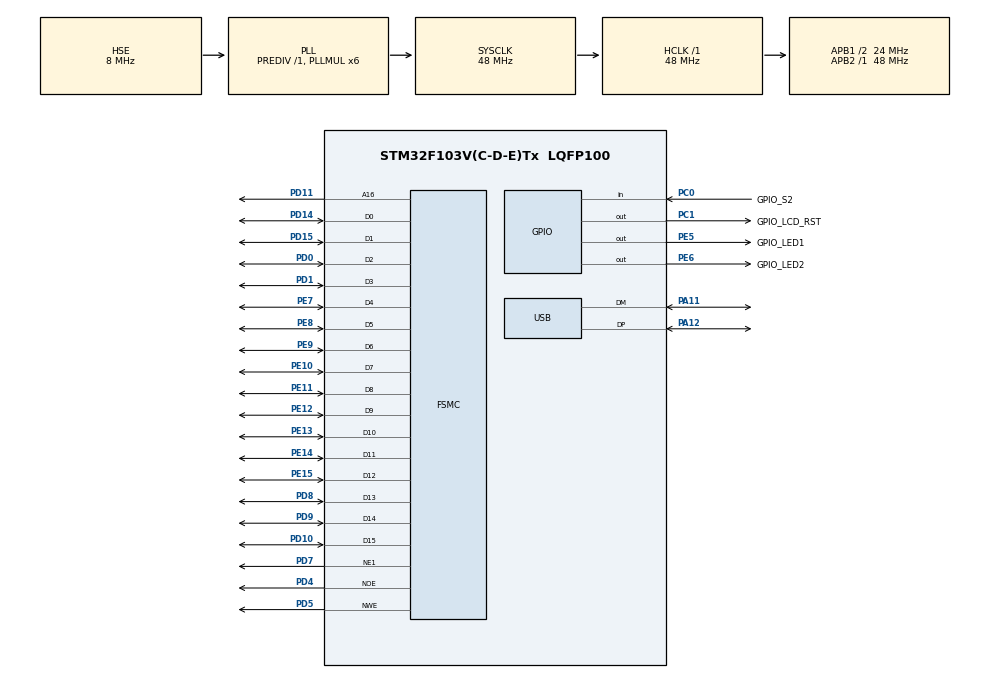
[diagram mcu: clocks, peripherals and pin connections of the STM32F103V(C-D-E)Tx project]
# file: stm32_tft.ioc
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Mcu.Family=STM32F1
Mcu.Name=STM32F103V(C-D-E)Tx
Mcu.Package=LQFP100
NVIC.PriorityGroup=NVIC_PRIORITYGROUP_4
NVIC.TIM6_IRQn=true\:0\:0\:false\:false\:true
NVIC.USB_LP_CAN1_RX0_IRQn=true\:0\:0\:false\:false\:true
OSC_IN.Mode=HSE-External-Oscillator
OSC_IN.Signal=RCC_OSC_IN
OSC_OUT.Mode=HSE-External-Oscillator
OSC_OUT.Signal=RCC_OSC_OUT
PA11.Mode=Device
PA11.Signal=USB_DM
PA12.Mode=Device
PA12.Signal=USB_DP
PA13.Mode=Serial_Wire
PA13.Signal=SYS_JTMS-SWDIO
PA14.Mode=Serial_Wire
PA14.Signal=SYS_JTCK-SWCLK
PC0.GPIO_Label=GPIO_S2
PC0.Signal=GPIO_Input
PC1.GPIO_Label=GPIO_LCD_RST
PC1.Signal=GPIO_Output
PC14-OSC32_IN.Mode=LSE-External-Oscillator
PC14-OSC32_IN.Signal=RCC_OSC32_IN
PC15-OSC32_OUT.Mode=LSE-External-Oscillator
PC15-OSC32_OUT.Signal=RCC_OSC32_OUT
PD0.Mode=16b-d1
PD0.Signal=FSMC_D2
PD1.Mode=16b-d1
PD1.Signal=FSMC_D3
PD10.Mode=16b-d1
PD10.Signal=FSMC_D15
PD11.Mode=A16_1
PD11.Signal=FSMC_A16
PD14.Mode=16b-d1
PD14.Signal=FSMC_D0
PD15.Mode=16b-d1
PD15.Signal=FSMC_D1
PD4.Mode=Lcd1
PD4.Signal=FSMC_NOE
PD5.Mode=Lcd1
PD5.Signal=FSMC_NWE
PD7.Mode=NorPsramChipSelect1_1
PD7.Signal=FSMC_NE1
PD8.Mode=16b-d1
PD8.Signal=FSMC_D13
PD9.Mode=16b-d1
PD9.Signal=FSMC_D14
PE10.Mode=16b-d1
PE10.Signal=FSMC_D7
PE11.Mode=16b-d1
PE11.Signal=FSMC_D8
PE12.Mode=16b-d1
PE12.Signal=FSMC_D9
PE13.Mode=16b-d1
PE13.Signal=FSMC_D10
PE14.Mode=16b-d1
PE14.Signal=FSMC_D11
PE15.Mode=16b-d1
PE15.Signal=FSMC_D12
PE5.GPIO_Label=GPIO_LED1
PE5.Signal=GPIO_Output
PE6.GPIO_Label=GPIO_LED2
PE6.Signal=GPIO_Output
PE7.Mode=16b-d1
PE7.Signal=FSMC_D4
PE8.Mode=16b-d1
PE8.Signal=FSMC_D5
PE9.Mode=16b-d1
PE9.Signal=FSMC_D6
ProjectManager.HeapSize=0x200
ProjectManager.StackSize=0x400
ProjectManager.TargetToolchain=SW4STM32
RCC.AHBFreq_Value=48000000
RCC.APB1CLKDivider=RCC_HCLK_DIV2
RCC.APB1Freq_Value=24000000
RCC.APB1TimFreq_Value=48000000
RCC.APB2Freq_Value=48000000
RCC.APB2TimFreq_Value=48000000
RCC.EnbaleCSS=true
RCC.HCLKFreq_Value=48000000
RCC.HSIState=RCC_HSI_ON
RCC.PLLMUL=RCC_PLL_MUL6
RCC.PLLSourceVirtual=RCC_PLLSOURCE_HSE
RCC.RTCClockSelection=RCC_RTCCLKSOURCE_LSE
RCC.SYSCLKFreq_VALUE=48000000
RCC.SYSCLKSource=RCC_SYSCLKSOURCE_PLLCLK
RCC.USBFreq_Value=48000000
TIM6.Period=48000
TIM6.Prescaler=0
TIM6.TIM_MasterOutputTrigger=TIM_TRGO_ENABLE
USB.ep0_mps=DEP0CTL_MPS_64
USB_DEVICE.CLASS_NAME_FS=CDC
USB_DEVICE.USBD_HandleTypeDef=hUsbDeviceFS
USB_DEVICE.VirtualMode=Cdc
USB_DEVICE.VirtualModeFS=Cdc_FS
VP_RTC_VS_RTC_Activate.Mode=RTC_Enabled
VP_TIM6_VS_ClockSourceINT.Mode=Enable_Timer
VP_USB_DEVICE_VS_USB_DEVICE_CDC_FS.Mode=CDC_FS
board=stm32_tft

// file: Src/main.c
/**
  ******************************************************************************
  * File Name          : main.c
  * Description        : Main program body
  ******************************************************************************
  *
  * Copyright (c) 2017 STMicroelectronics International N.V.
  * All rights reserved.
  *
  * Redistribution and use in source and binary forms, with or without
  * modification, are permitted, provided that the following conditions are met:
  *
  * 1. Redistribution of source code must retain the above copyright notice,
  *    this list of conditions and the following disclaimer.
  * 2. Redistributions in binary form must reproduce the above copyright notice,
  *    this list of conditions and the following disclaimer in the documentation
  *    and/or other materials provided with the distribution.
  * 3. Neither the name of STMicroelectronics nor the names of other
  *    contributors to this software may be used to endorse or promote products
  *    derived from this software without specific written permission.
  * 4. This software, including modifications and/or derivative works of this
  *    software, must execute solely and exclusively on microcontroller or
  *    microprocessor devices manufactured by or for STMicroelectronics.
  * 5. Redistribution and use of this software other than as permitted under
  *    this license is void and will automatically terminate your rights under
  *    this license.
  *
  * THIS SOFTWARE IS PROVIDED BY STMICROELECTRONICS AND CONTRIBUTORS "AS IS"
  * AND ANY EXPRESS, IMPLIED OR STATUTORY WARRANTIES, INCLUDING, BUT NOT
  * LIMITED TO, THE IMPLIED WARRANTIES OF MERCHANTABILITY, FITNESS FOR A
  * PARTICULAR PURPOSE AND NON-INFRINGEMENT OF THIRD PARTY INTELLECTUAL PROPERTY
  * RIGHTS ARE DISCLAIMED TO THE FULLEST EXTENT PERMITTED BY LAW. IN NO EVENT
  * SHALL STMICROELECTRONICS OR CONTRIBUTORS BE LIABLE FOR ANY DIRECT, INDIRECT,
  * INCIDENTAL, SPECIAL, EXEMPLARY, OR CONSEQUENTIAL DAMAGES (INCLUDING, BUT NOT
  * LIMITED TO, PROCUREMENT OF SUBSTITUTE GOODS OR SERVICES; LOSS OF USE, DATA,
  * OR PROFITS; OR BUSINESS INTERRUPTION) HOWEVER CAUSED AND ON ANY THEORY OF
  * LIABILITY, WHETHER IN CONTRACT, STRICT LIABILITY, OR TORT (INCLUDING
  * NEGLIGENCE OR OTHERWISE) ARISING IN ANY WAY OUT OF THE USE OF THIS SOFTWARE,
  * EVEN IF ADVISED OF THE POSSIBILITY OF SUCH DAMAGE.
  *
  ******************************************************************************
  */
#include "main.h"
#include "stm32f1xx_hal.h"
#include "usb_device.h"

/* USER CODE BEGIN Includes */
//#include "stm32_microrl_misc.h"
#include "event_queue.h"
#include "timer.h"
/* USER CODE END Includes */

RTC_HandleTypeDef hrtc;

TIM_HandleTypeDef htim6;

/* USER CODE BEGIN PV */
/* Private variables ---------------------------------------------------------*/

/* USER CODE END PV */

void SystemClock_Config(void);
void Error_Handler(void);
static void MX_GPIO_Init(void);
static void MX_RTC_Init(void);
static void MX_TIM6_Init(void);

/* USER CODE BEGIN PFP */
/* Private function prototypes -----------------------------------------------*/

/* USER CODE END PFP */

/* USER CODE BEGIN 0 */
//arm-none-eabi-objcopy -O binary "${BuildArtifactFileBaseName}.elf" "${BuildArtifactFileBaseName}.bin" && arm-none-eabi-size "${BuildArtifactFileName}"
//arm-none-eabi-objcopy -O ihex "${BuildArtifactFileBaseName}.elf" "${BuildArtifactFileBaseName}.hex"
/* USER CODE END 0 */

int main(void)
{

  /* USER CODE BEGIN 1 */
	eq_queue_element_s ev;
  /* USER CODE END 1 */

  /* MCU Configuration----------------------------------------------------------*/

  /* Reset of all peripherals, Initializes the Flash interface and the Systick. */
  HAL_Init();

  /* Configure the system clock */
  SystemClock_Config();

  /* Initialize all configured peripherals */
  MX_GPIO_Init();
  MX_RTC_Init();
  MX_TIM6_Init();
  MX_USB_DEVICE_Init();

  /* USER CODE BEGIN 2 */
//  init();
  HAL_TIM_Base_Start_IT(&htim6);
  HAL_GPIO_WritePin(GPIO_LED1_GPIO_Port, GPIO_LED1_Pin, GPIO_PIN_SET);
  HAL_GPIO_WritePin(GPIO_LED2_GPIO_Port, GPIO_LED2_Pin, GPIO_PIN_RESET);
  TIMER_StartAuto(1, 50);
  /* USER CODE END 2 */

  /* Infinite loop */
  /* USER CODE BEGIN WHILE */
  while (1)
  {
//	  TERM_Task();
	  TIMER_Task();
	  do {
		  EQ_GetEvent(&ev);
		  switch(ev.event){
		  case NO_EVENT:
			  break;
		  case CMD_WIDTH:
		  	  TIMER_StartAuto(1, ev.param.uiParam);
		  	  break;
		  case CMD_HV_ON:
			  HAL_GPIO_WritePin(GPIO_LED2_GPIO_Port, GPIO_LED2_Pin, GPIO_PIN_RESET);
			  break;
		  case CMD_HV_OFF:
			  HAL_GPIO_WritePin(GPIO_LED2_GPIO_Port, GPIO_LED2_Pin, GPIO_PIN_SET);
			  break;
		  case TIMER1_EXPIRED:
			  //HAL_GPIO_TogglePin(GPIO_LED1_GPIO_Port, GPIO_LED1_Pin);
			  //HAL_GPIO_TogglePin(GPIO_LED2_GPIO_Port, GPIO_LED2_Pin);
			  break;
		  default:
			  break;
		  }
	  } while (ev.event != NO_EVENT);
  }
  /* USER CODE END WHILE */

  /* USER CODE BEGIN 3 */
//	  uint8_t Buf[100] = "";
//	  sprintf(Buf,"cnt 0x%08d    ", int_counter);
//
//	  CDC_Transmit_FS(Buf, 15);
//	  HAL_Delay(1000);
//	  if (1 == blink)
//	  {
//		  HAL_GPIO_WritePin(GPIO_LED1_GPIO_Port, GPIO_LED1_Pin, GPIO_PIN_SET);
//		  blink = 0;
//	  } else {
//		  HAL_GPIO_WritePin(GPIO_LED1_GPIO_Port, GPIO_LED1_Pin, GPIO_PIN_RESET);
//		  blink = 1;
//	  }

  /* USER CODE END 3 */

}

/** System Clock Configuration
*/
void SystemClock_Config(void)
{

  RCC_OscInitTypeDef RCC_OscInitStruct;
  RCC_ClkInitTypeDef RCC_ClkInitStruct;
  RCC_PeriphCLKInitTypeDef PeriphClkInit;

    /**Initializes the CPU, AHB and APB busses clocks
    */
  RCC_OscInitStruct.OscillatorType = RCC_OSCILLATORTYPE_HSE|RCC_OSCILLATORTYPE_LSE;
  RCC_OscInitStruct.HSEState = RCC_HSE_ON;
  RCC_OscInitStruct.HSEPredivValue = RCC_HSE_PREDIV_DIV1;
  RCC_OscInitStruct.LSEState = RCC_LSE_ON;
  RCC_OscInitStruct.HSIState = RCC_HSI_ON;
  RCC_OscInitStruct.PLL.PLLState = RCC_PLL_ON;
  RCC_OscInitStruct.PLL.PLLSource = RCC_PLLSOURCE_HSE;
  RCC_OscInitStruct.PLL.PLLMUL = RCC_PLL_MUL6;
  if (HAL_RCC_OscConfig(&RCC_OscInitStruct) != HAL_OK)
  {
    Error_Handler();
  }

    /**Initializes the CPU, AHB and APB busses clocks
    */
  RCC_ClkInitStruct.ClockType = RCC_CLOCKTYPE_HCLK|RCC_CLOCKTYPE_SYSCLK
                              |RCC_CLOCKTYPE_PCLK1|RCC_CLOCKTYPE_PCLK2;
  RCC_ClkInitStruct.SYSCLKSource = RCC_SYSCLKSOURCE_PLLCLK;
  RCC_ClkInitStruct.AHBCLKDivider = RCC_SYSCLK_DIV1;
  RCC_ClkInitStruct.APB1CLKDivider = RCC_HCLK_DIV2;
  RCC_ClkInitStruct.APB2CLKDivider = RCC_HCLK_DIV1;

  if (HAL_RCC_ClockConfig(&RCC_ClkInitStruct, FLASH_LATENCY_1) != HAL_OK)
  {
    Error_Handler();
  }

  PeriphClkInit.PeriphClockSelection = RCC_PERIPHCLK_RTC|RCC_PERIPHCLK_USB;
  PeriphClkInit.RTCClockSelection = RCC_RTCCLKSOURCE_LSE;
  PeriphClkInit.UsbClockSelection = RCC_USBCLKSOURCE_PLL;
  if (HAL_RCCEx_PeriphCLKConfig(&PeriphClkInit) != HAL_OK)
  {
    Error_Handler();
  }

    /**Enables the Clock Security System
    */
  HAL_RCC_EnableCSS();

    /**Configure the Systick interrupt time
    */
  HAL_SYSTICK_Config(HAL_RCC_GetHCLKFreq()/1000);

    /**Configure the Systick
    */
  HAL_SYSTICK_CLKSourceConfig(SYSTICK_CLKSOURCE_HCLK);

  /* SysTick_IRQn interrupt configuration */
  HAL_NVIC_SetPriority(SysTick_IRQn, 0, 0);
}

/* RTC init function */
static void MX_RTC_Init(void)
{

    /**Initialize RTC Only
    */
  hrtc.Instance = RTC;
  hrtc.Init.AsynchPrediv = RTC_AUTO_1_SECOND;
  hrtc.Init.OutPut = RTC_OUTPUTSOURCE_ALARM;
  if (HAL_RTC_Init(&hrtc) != HAL_OK)
  {
    Error_Handler();
  }

}

/* TIM6 init function */
static void MX_TIM6_Init(void)
{

  TIM_MasterConfigTypeDef sMasterConfig;

  htim6.Instance = TIM6;
  htim6.Init.Prescaler = 0;
  htim6.Init.CounterMode = TIM_COUNTERMODE_UP;
  htim6.Init.Period = 48000;
  if (HAL_TIM_Base_Init(&htim6) != HAL_OK)
  {
    Error_Handler();
  }

  sMasterConfig.MasterOutputTrigger = TIM_TRGO_ENABLE;
  sMasterConfig.MasterSlaveMode = TIM_MASTERSLAVEMODE_DISABLE;
  if (HAL_TIMEx_MasterConfigSynchronization(&htim6, &sMasterConfig) != HAL_OK)
  {
    Error_Handler();
  }

}

/** Configure pins as
        * Analog
        * Input
        * Output
        * EVENT_OUT
        * EXTI
*/
static void MX_GPIO_Init(void)
{

  GPIO_InitTypeDef GPIO_InitStruct;

  /* GPIO Ports Clock Enable */
  __HAL_RCC_GPIOE_CLK_ENABLE();
  __HAL_RCC_GPIOC_CLK_ENABLE();
  __HAL_RCC_GPIOA_CLK_ENABLE();

  /*Configure GPIO pin Output Level */
  HAL_GPIO_WritePin(GPIOE, GPIO_LED1_Pin|GPIO_LED2_Pin, GPIO_PIN_RESET);

  /*Configure GPIO pins : GPIO_LED1_Pin GPIO_LED2_Pin */
  GPIO_InitStruct.Pin = GPIO_LED1_Pin|GPIO_LED2_Pin;
  GPIO_InitStruct.Mode = GPIO_MODE_OUTPUT_PP;
  GPIO_InitStruct.Speed = GPIO_SPEED_FREQ_LOW;
  HAL_GPIO_Init(GPIOE, &GPIO_InitStruct);

  /*Configure GPIO pins : GPIO_S2_Pin GPIO_S3_Pin */
  GPIO_InitStruct.Pin = GPIO_S2_Pin|GPIO_S3_Pin;
  GPIO_InitStruct.Mode = GPIO_MODE_INPUT;
  GPIO_InitStruct.Pull = GPIO_NOPULL;
  HAL_GPIO_Init(GPIOC, &GPIO_InitStruct);

}

void Error_Handler(void)
{
  while(1)
  {
  }
}

/************************ (C) COPYRIGHT STMicroelectronics *****END OF FILE****/
